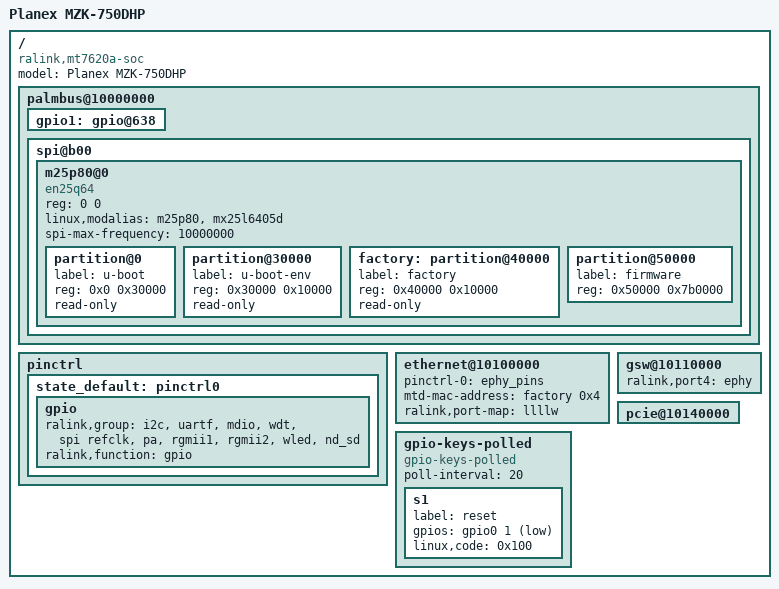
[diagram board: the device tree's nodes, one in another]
/dts-v1/;

/include/ "mt7620a.dtsi"

/ {
	compatible = "ralink,mt7620a-soc";
	model = "Planex MZK-750DHP";

	palmbus@10000000 {
		gpio1: gpio@638 {
			status = "okay";
		};

		spi@b00 {
			status = "okay";

			m25p80@0 {
				#address-cells = <1>;
				#size-cells = <1>;
				compatible = "en25q64";
				reg = <0 0>;
				linux,modalias = "m25p80", "mx25l6405d";
				spi-max-frequency = <10000000>;

				partition@0 {
					label = "u-boot";
					reg = <0x0 0x30000>;
					read-only;
				};

				partition@30000 {
					label = "u-boot-env";
					reg = <0x30000 0x10000>;
					read-only;
				};

				factory: partition@40000 {
					label = "factory";
					reg = <0x40000 0x10000>;
					read-only;
				};

				partition@50000 {
					label = "firmware";
					reg = <0x50000 0x7b0000>;
				};
			};
		};
	};

	pinctrl {
		state_default: pinctrl0 {
			gpio {
				ralink,group = "i2c", "uartf", "mdio", "wdt", "spi refclk", "pa", "rgmii1", "rgmii2", "wled", "nd_sd";
				ralink,function = "gpio";
			};
		};
	};

	ethernet@10100000 {
		pinctrl-names = "default";
		pinctrl-0 = <&ephy_pins>;

		mtd-mac-address = <&factory 0x4>;
		ralink,port-map = "llllw";
	};

	gsw@10110000 {
		ralink,port4 = "ephy";
	};

	pcie@10140000 {
		status = "okay";
	};
	
	gpio-keys-polled {
		compatible = "gpio-keys-polled";
		#address-cells = <1>;
		#size-cells = <0>;
		poll-interval = <20>;
		s1 {
			label = "reset";
			gpios = <&gpio0 1 1>;
			linux,code = <0x100>;
		};
	};
};
